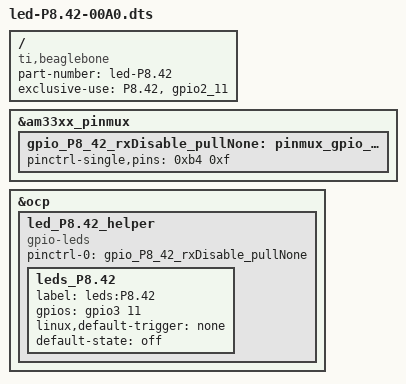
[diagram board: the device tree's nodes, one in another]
/*
* Easy gpio mux control of "P8.42" ("gpio2_11")
*/
/dts-v1/;
/plugin/;

/ {
	compatible = "ti,beaglebone", "ti,beaglebone-black";

	/* identification */
	part-number = "led-P8.42";
	/* version = "00A0"; */

	/* state the resources this cape uses */
	exclusive-use =
		/* the pin header uses */
		"P8.42",

		/* the hardware IP uses */
		"gpio2_11";
	
	
	/* rxDisable_pullNone state */
	fragment@0 {
		target = <&am33xx_pinmux>;
		__overlay__ {
			gpio_P8_42_rxDisable_pullNone: pinmux_gpio_P8.42_rxDisable_pullNone {
				pinctrl-single,pins = <
					0xb4 0xf
				>;
			};
		};
	};

	fragment@1 {
		target = <&ocp>;
		__overlay__ {
			led_P8.42_helper {
				compatible = "gpio-leds";
				pinctrl-names = "default";
				pinctrl-0 = <&gpio_P8_42_rxDisable_pullNone>;
				
				leds_P8.42 {
					label = "leds:P8.42";
					gpios = <&gpio3 11 0>;
					linux,default-trigger = "none";
					default-state = "off";
				};
			};
			
		};
	};

};
